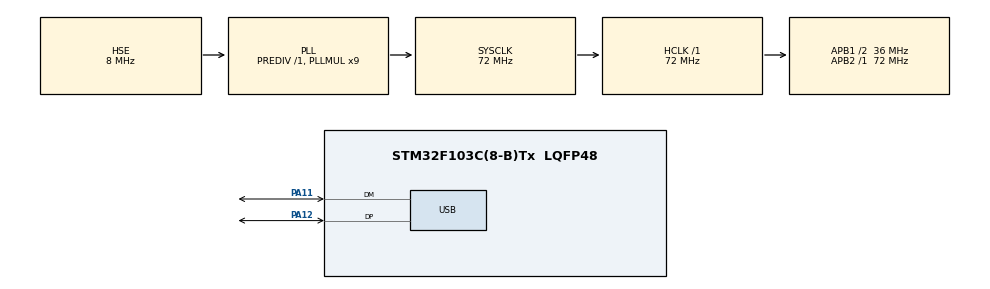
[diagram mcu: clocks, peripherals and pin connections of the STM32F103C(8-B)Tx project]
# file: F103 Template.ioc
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Mcu.Family=STM32F1
Mcu.Name=STM32F103C(8-B)Tx
Mcu.Package=LQFP48
NVIC.PriorityGroup=NVIC_PRIORITYGROUP_4
NVIC.USB_LP_CAN1_RX0_IRQn=true\:0\:0\:false\:false\:true\:false
PA11.Mode=Device
PA11.Signal=USB_DM
PA12.Mode=Device
PA12.Signal=USB_DP
PA13.Mode=Serial_Wire
PA13.Signal=SYS_JTMS-SWDIO
PA14.Mode=Serial_Wire
PA14.Signal=SYS_JTCK-SWCLK
PD0-OSC_IN.Mode=HSE-External-Oscillator
PD0-OSC_IN.Signal=RCC_OSC_IN
PD1-OSC_OUT.Mode=HSE-External-Oscillator
PD1-OSC_OUT.Signal=RCC_OSC_OUT
ProjectManager.HeapSize=0x200
ProjectManager.StackSize=0x400
ProjectManager.TargetToolchain=Makefile
RCC.AHBFreq_Value=72000000
RCC.APB1CLKDivider=RCC_HCLK_DIV2
RCC.APB1Freq_Value=36000000
RCC.APB1TimFreq_Value=72000000
RCC.APB2Freq_Value=72000000
RCC.APB2TimFreq_Value=72000000
RCC.HCLKFreq_Value=72000000
RCC.OscillatorTypeHSE-ClockTree=RCC_OSCILLATORTYPE_HSE
RCC.PLLMUL=RCC_PLL_MUL9
RCC.PLLSourceVirtual=RCC_PLLSOURCE_HSE
RCC.RTCEnable-ClockTree=true
RCC.SYSCLKFreq_VALUE=72000000
RCC.SYSCLKSource=RCC_SYSCLKSOURCE_PLLCLK
RCC.USBFreq_Value=48000000
RCC.USBPrescaler=RCC_USBCLKSOURCE_PLL_DIV1_5
USB_DEVICE.CLASS_NAME_FS=HID
USB_DEVICE.VirtualMode=Hid
USB_DEVICE.VirtualModeFS=Hid_FS
VP_USB_DEVICE_VS_USB_DEVICE_HID_FS.Mode=HID_FS
board=custom

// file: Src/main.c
/* USER CODE BEGIN Header */
/**
  ******************************************************************************
  * @file           : main.c
  * @brief          : Main program body
  ******************************************************************************
  ** This notice applies to any and all portions of this file
  * that are not between comment pairs USER CODE BEGIN and
  * USER CODE END. Other portions of this file, whether
  * inserted by the user or by software development tools
  * are owned by their respective copyright owners.
  *
  * COPYRIGHT(c) 2019 STMicroelectronics
  *
  * Redistribution and use in source and binary forms, with or without modification,
  * are permitted provided that the following conditions are met:
  *   1. Redistributions of source code must retain the above copyright notice,
  *      this list of conditions and the following disclaimer.
  *   2. Redistributions in binary form must reproduce the above copyright notice,
  *      this list of conditions and the following disclaimer in the documentation
  *      and/or other materials provided with the distribution.
  *   3. Neither the name of STMicroelectronics nor the names of its contributors
  *      may be used to endorse or promote products derived from this software
  *      without specific prior written permission.
  *
  * THIS SOFTWARE IS PROVIDED BY THE COPYRIGHT HOLDERS AND CONTRIBUTORS "AS IS"
  * AND ANY EXPRESS OR IMPLIED WARRANTIES, INCLUDING, BUT NOT LIMITED TO, THE
  * IMPLIED WARRANTIES OF MERCHANTABILITY AND FITNESS FOR A PARTICULAR PURPOSE ARE
  * DISCLAIMED. IN NO EVENT SHALL THE COPYRIGHT HOLDER OR CONTRIBUTORS BE LIABLE
  * FOR ANY DIRECT, INDIRECT, INCIDENTAL, SPECIAL, EXEMPLARY, OR CONSEQUENTIAL
  * DAMAGES (INCLUDING, BUT NOT LIMITED TO, PROCUREMENT OF SUBSTITUTE GOODS OR
  * SERVICES; LOSS OF USE, DATA, OR PROFITS; OR BUSINESS INTERRUPTION) HOWEVER
  * CAUSED AND ON ANY THEORY OF LIABILITY, WHETHER IN CONTRACT, STRICT LIABILITY,
  * OR TORT (INCLUDING NEGLIGENCE OR OTHERWISE) ARISING IN ANY WAY OUT OF THE USE
  * OF THIS SOFTWARE, EVEN IF ADVISED OF THE POSSIBILITY OF SUCH DAMAGE.
  *
  ******************************************************************************
  */
/* USER CODE END Header */

#include "main.h"
#include "usb_device.h"

/* USER CODE BEGIN Includes */
#include "usbd_hid.h"
/* USER CODE END Includes */

/* USER CODE BEGIN PV */
extern USBD_HandleTypeDef hUsbDeviceFS;
#define PRESS_REPORT_SIZE 8
/* USER CODE END PV */

void SystemClock_Config(void);
static void MX_GPIO_Init(void);

int main(void)
{
  /* USER CODE BEGIN 1 */
  uint8_t press_report[PRESS_REPORT_SIZE] = {0};
  /* USER CODE END 1 */

  /* MCU Configuration--------------------------------------------------------*/

  /* Reset of all peripherals, Initializes the Flash interface and the Systick. */
  HAL_Init();

  /* Configure the system clock */
  SystemClock_Config();

  /* Initialize all configured peripherals */
  MX_GPIO_Init();
  MX_USB_DEVICE_Init();

  /* Infinite loop */
  while (1)
  {
    /* USER CODE BEGIN 3 */
    press_report[2] = 15;  // send 'l'
    press_report[3] = 16;  // send 'm'
    press_report[4] = 4;  // send 'a'
    press_report[5] = 18;  // send 'o'
    // press_report[6] = 17;  // send 'n'

    USBD_HID_SendReport(&hUsbDeviceFS, press_report, PRESS_REPORT_SIZE);

    HAL_Delay(50);

    //press_report[2] = 0;  // send button release
    press_report[2] = 0;
    press_report[3] = 0;
    press_report[4] = 0;
    press_report[5] = 0;
    // press_report[6] = 0;

    USBD_HID_SendReport(&hUsbDeviceFS, press_report, PRESS_REPORT_SIZE);
    HAL_Delay(10);
    HAL_GPIO_TogglePin(GPIOC, GPIO_PIN_13);
    HAL_Delay(400);
    HAL_GPIO_TogglePin(GPIOC, GPIO_PIN_13);
    HAL_Delay(400);
  }
  /* USER CODE END 3 */
}

void SystemClock_Config(void)
{/*
  RCC_OscInitTypeDef RCC_OscInitStruct = {0};
  RCC_ClkInitTypeDef RCC_ClkInitStruct = {0};
  RCC_OscInitStruct.OscillatorType = RCC_OSCILLATORTYPE_HSE;
  RCC_OscInitStruct.HSEState = RCC_HSE_ON;
  RCC_OscInitStruct.HSEPredivValue = RCC_HSE_PREDIV_DIV1;
  RCC_OscInitStruct.HSIState = RCC_HSI_ON;
  RCC_OscInitStruct.PLL.PLLState = RCC_PLL_ON;
  RCC_OscInitStruct.PLL.PLLSource = RCC_PLLSOURCE_HSE;
  RCC_OscInitStruct.PLL.PLLMUL = RCC_PLL_MUL9;
  if (HAL_RCC_OscConfig(&RCC_OscInitStruct) != HAL_OK)
  {
    Error_Handler();
  }
  RCC_ClkInitStruct.ClockType = RCC_CLOCKTYPE_HCLK|RCC_CLOCKTYPE_SYSCLK
                              |RCC_CLOCKTYPE_PCLK1|RCC_CLOCKTYPE_PCLK2;
  RCC_ClkInitStruct.SYSCLKSource = RCC_SYSCLKSOURCE_PLLCLK;
  RCC_ClkInitStruct.AHBCLKDivider = RCC_SYSCLK_DIV1;
  RCC_ClkInitStruct.APB1CLKDivider = RCC_HCLK_DIV2;
  RCC_ClkInitStruct.APB2CLKDivider = RCC_HCLK_DIV1;

  if (HAL_RCC_ClockConfig(&RCC_ClkInitStruct, FLASH_LATENCY_2) != HAL_OK)
  {
    Error_Handler();
  }*/

  /*
  RCC_OscInitTypeDef RCC_OscInitStruct = {0};
  RCC_ClkInitTypeDef RCC_ClkInitStruct = {0};
  RCC_PeriphCLKInitTypeDef PeriphClkInit = {0};
  RCC_OscInitStruct.OscillatorType = RCC_OSCILLATORTYPE_HSE;
  RCC_OscInitStruct.HSEPredivValue = RCC_HSE_PREDIV_DIV1;
  RCC_OscInitStruct.HSIState = RCC_HSI_ON;
  RCC_OscInitStruct.PLL.PLLState = RCC_PLL_ON;
  RCC_OscInitStruct.PLL.PLLSource = RCC_PLLSOURCE_HSE;
  RCC_OscInitStruct.PLL.PLLMUL = RCC_PLL_MUL9;
  if (HAL_RCC_OscConfig(&RCC_OscInitStruct) != HAL_OK)
  {
    Error_Handler();
  }
  RCC_ClkInitStruct.ClockType = RCC_CLOCKTYPE_HCLK|RCC_CLOCKTYPE_SYSCLK
                              |RCC_CLOCKTYPE_PCLK1|RCC_CLOCKTYPE_PCLK2;
  RCC_ClkInitStruct.SYSCLKSource = RCC_SYSCLKSOURCE_PLLCLK;
  RCC_ClkInitStruct.AHBCLKDivider = RCC_SYSCLK_DIV1;
  RCC_ClkInitStruct.APB1CLKDivider = RCC_HCLK_DIV2;
  RCC_ClkInitStruct.APB2CLKDivider = RCC_HCLK_DIV1;

  if (HAL_RCC_ClockConfig(&RCC_ClkInitStruct, FLASH_LATENCY_2) != HAL_OK)
  {
    Error_Handler();
  }
  PeriphClkInit.PeriphClockSelection = RCC_PERIPHCLK_USB;
  PeriphClkInit.UsbClockSelection = RCC_USBCLKSOURCE_PLL_DIV1_5;
  if (HAL_RCCEx_PeriphCLKConfig(&PeriphClkInit) != HAL_OK)
  {
    Error_Handler();
  }*/

  RCC_OscInitTypeDef RCC_OscInitStruct = {0};
  RCC_ClkInitTypeDef RCC_ClkInitStruct = {0};
  RCC_PeriphCLKInitTypeDef PeriphClkInit = {0};
  RCC_OscInitStruct.OscillatorType = RCC_OSCILLATORTYPE_HSE;
  RCC_OscInitStruct.HSEState = RCC_HSE_ON;
  RCC_OscInitStruct.HSEPredivValue = RCC_HSE_PREDIV_DIV1;
  RCC_OscInitStruct.HSIState = RCC_HSI_ON;
  RCC_OscInitStruct.PLL.PLLState = RCC_PLL_ON;
  RCC_OscInitStruct.PLL.PLLSource = RCC_PLLSOURCE_HSE;
  RCC_OscInitStruct.PLL.PLLMUL = RCC_PLL_MUL9;
  if (HAL_RCC_OscConfig(&RCC_OscInitStruct) != HAL_OK)
  {
    Error_Handler();
  }
  RCC_ClkInitStruct.ClockType = RCC_CLOCKTYPE_HCLK|RCC_CLOCKTYPE_SYSCLK
                              |RCC_CLOCKTYPE_PCLK1|RCC_CLOCKTYPE_PCLK2;
  RCC_ClkInitStruct.SYSCLKSource = RCC_SYSCLKSOURCE_PLLCLK;
  RCC_ClkInitStruct.AHBCLKDivider = RCC_SYSCLK_DIV1;
  RCC_ClkInitStruct.APB1CLKDivider = RCC_HCLK_DIV2;
  RCC_ClkInitStruct.APB2CLKDivider = RCC_HCLK_DIV1;

  if (HAL_RCC_ClockConfig(&RCC_ClkInitStruct, FLASH_LATENCY_2) != HAL_OK)
  {
    Error_Handler();
  }
  PeriphClkInit.PeriphClockSelection = RCC_PERIPHCLK_USB;
  PeriphClkInit.UsbClockSelection = RCC_USBCLKSOURCE_PLL_DIV1_5;
  if (HAL_RCCEx_PeriphCLKConfig(&PeriphClkInit) != HAL_OK)
  {
    Error_Handler();
  }
}
static void MX_GPIO_Init(void)
{
  GPIO_InitTypeDef GPIO_InitStructPC = {0};
  /* GPIO Ports Clock Enable */
  __HAL_RCC_GPIOD_CLK_ENABLE();
  __HAL_RCC_GPIOC_CLK_ENABLE();
  __HAL_RCC_GPIOA_CLK_ENABLE();

  GPIO_InitStructPC.Pin = GPIO_PIN_13;
  GPIO_InitStructPC.Mode = GPIO_MODE_OUTPUT_PP;
  GPIO_InitStructPC.Pull = GPIO_NOPULL;
  GPIO_InitStructPC.Speed = GPIO_SPEED_FREQ_MEDIUM;
  HAL_GPIO_Init(GPIOC, &GPIO_InitStructPC);

}

void Error_Handler(void)
{
}

/************************ (C) COPYRIGHT STMicroelectronics *****END OF FILE****/
